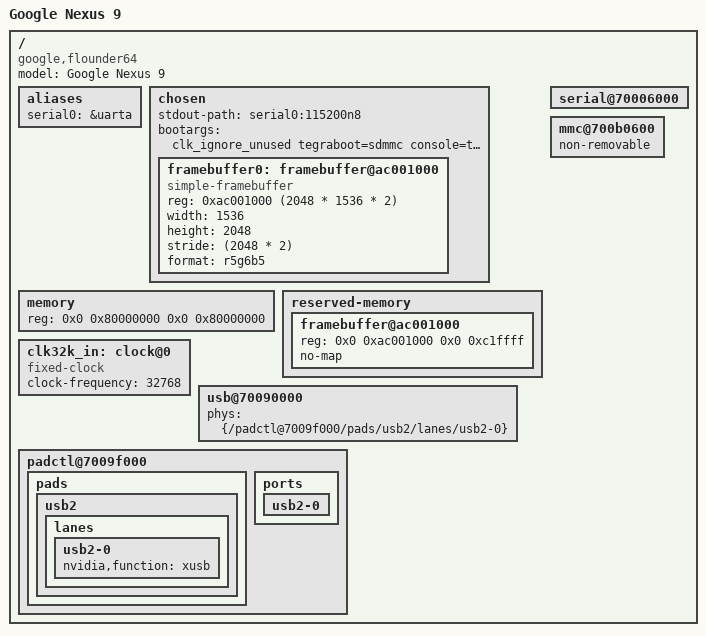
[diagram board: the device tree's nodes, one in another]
// SPDX-License-Identifier: GPL-2.0
/dts-v1/;

#include "tegra132.dtsi"

/ {

	model = "Google Nexus 9";
	compatible = "google,flounder64", "nvidia,tegra132";

	aliases {
		serial0 = &uarta;
	};

	chosen {
		stdout-path = "serial0:115200n8";
		bootargs = "clk_ignore_unused tegraboot=sdmmc console=tty1 PMOS_NO_OUTPUT_REDIRECT";

		framebuffer0: framebuffer@ac001000 {
			compatible = "simple-framebuffer";
			reg = <0xac001000 (2048 * 1536 * 2)>;
			width = <1536>;
			height = <2048>;
			stride = <(2048 * 2)>;
			format = "r5g6b5";
		};
	};

	memory {
		device_type = "memory";
		reg = <0x0 0x80000000 0x0 0x80000000>;
	};

	reserved-memory {
		framebuffer@ac001000 {
			reg = <0x0 0xac001000 0x0 0xc1ffff>;
			no-map;
		};
	};

	clk32k_in: clock@0 {
		compatible = "fixed-clock";
		#clock-cells = <0>;
		clock-frequency = <32768>;
	};

	serial@70006000 {
		status = "okay";
	};

	mmc@700b0600 {
		status = "okay";
		non-removable;
	};

	usb@70090000 {
		status = "okay";
		phys = <&{/padctl@7009f000/pads/usb2/lanes/usb2-0}>;
		phy-names = "usb2-0";
	};

	padctl@7009f000 {
		pads {
			usb2 {
				status = "okay";
				lanes {
					usb2-0 {
						nvidia,function = "xusb";
						status = "okay";
					};
				};
			};
		};

		ports {
			usb2-0 {
				status = "okay";
			};
		};
	};

};
